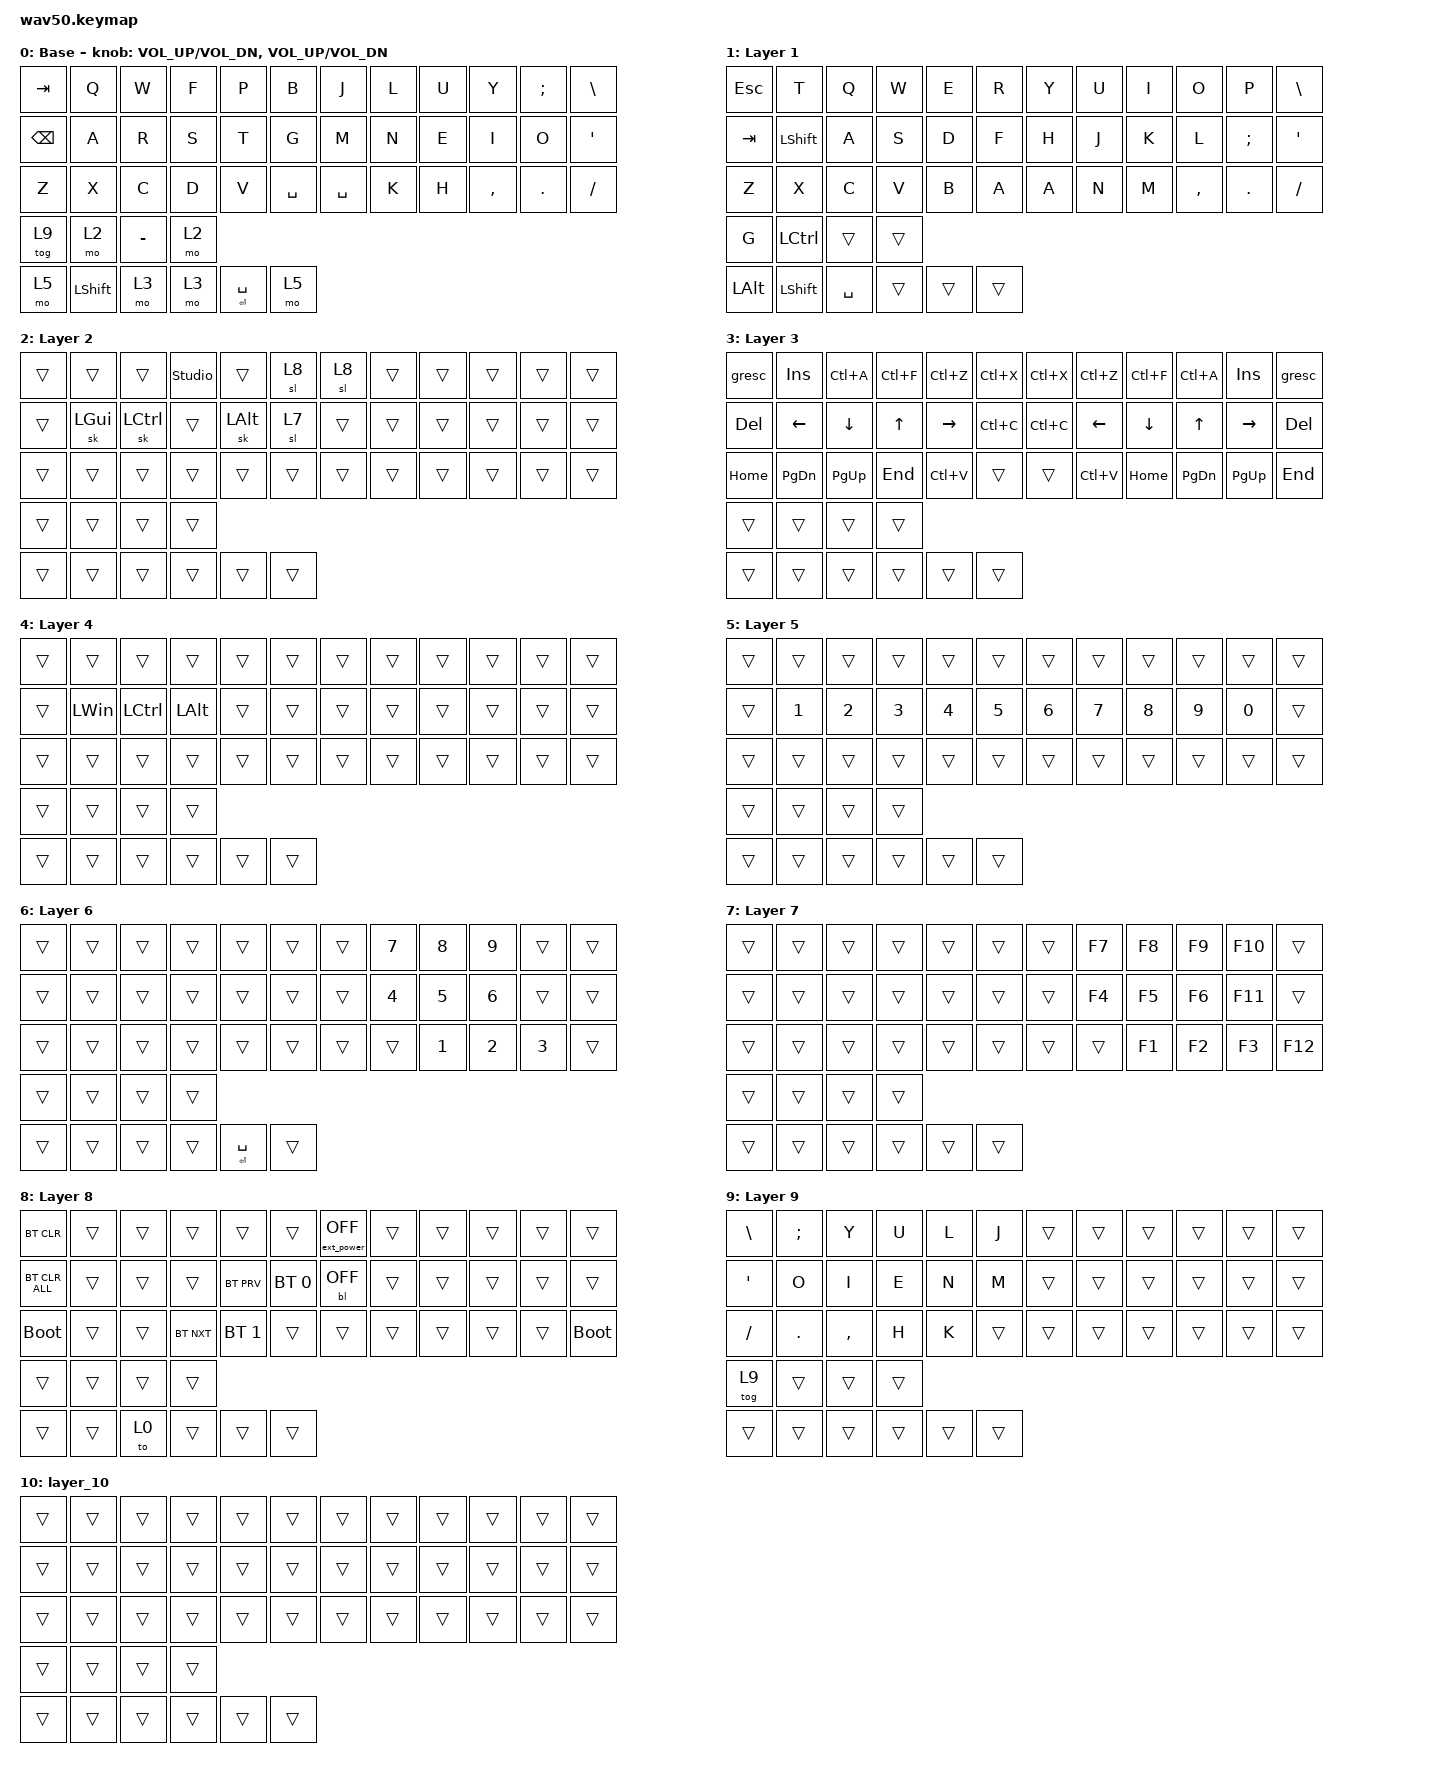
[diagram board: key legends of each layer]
#include <behaviors.dtsi>
#include <dt-bindings/zmk/backlight.h>
#include <dt-bindings/zmk/bt.h>
#include <dt-bindings/zmk/ext_power.h>
#include <dt-bindings/zmk/keys.h>

/ {
    behaviors {
        spc_ent: space_enter {
            compatible = "zmk,behavior-hold-tap";
            #binding-cells = <2>;
            flavor = "tap-preferred";
            tapping-term-ms = <350>;
            bindings = <&kp>, <&kp>;
        };
    };

    keymap {
        compatible = "zmk,keymap";

        default_layer {
            display-name = "Base";
            bindings = <
&kp TAB   &kp Q           &kp W      &kp F  &kp P          &kp B      &kp J      &kp L  &kp U  &kp Y      &kp SEMI  &kp BACKSLASH
&kp BSPC  &kp A           &kp R      &kp S  &kp T          &kp G      &kp M      &kp N  &kp E  &kp I      &kp O     &kp SQT
&kp Z     &kp X           &kp C      &kp D  &kp V          &kp SPACE  &kp SPACE  &kp K  &kp H  &kp COMMA  &kp DOT   &kp FSLH
&tog 9    &mo 2           &kp MINUS  &mo 2
&mo 5     &kp LEFT_SHIFT  &mo 3      &mo 3  &spc_ent RET SPACE  &mo 5
            >;

            sensor-bindings = <&inc_dec_kp C_VOL_UP C_VOL_DN &inc_dec_kp C_VOL_UP C_VOL_DN>;
        };

        low {
            display-name = "Layer 1";
            bindings = <
&kp ESC   &kp T      &kp Q      &kp W   &kp E   &kp R   &kp Y  &kp U  &kp I  &kp O      &kp P     &kp BSLH
&kp TAB   &kp LSHFT  &kp A      &kp S   &kp D   &kp F   &kp H  &kp J  &kp K  &kp L      &kp SEMI  &kp APOS
&kp Z     &kp X      &kp C      &kp V   &kp B   &kp A   &kp A  &kp N  &kp M  &kp COMMA  &kp DOT   &kp FSLH
&kp G     &kp LCTRL  &trans     &trans
&kp LALT  &kp LSHFT  &kp SPACE  &trans  &trans  &trans
            >;
        };

        up {
            display-name = "Layer 2";
            bindings = <
&trans  &trans        &trans            &studio_unlock  &trans        &sl 8   &sl 8   &trans  &trans  &trans  &trans  &trans
&trans  &sk LEFT_GUI  &sk LEFT_CONTROL  &trans          &sk LEFT_ALT  &sl 7   &trans  &trans  &trans  &trans  &trans  &trans
&trans  &trans        &trans            &trans          &trans        &trans  &trans  &trans  &trans  &trans  &trans  &trans
&trans  &trans        &trans            &trans
&trans  &trans        &trans            &trans          &trans        &trans
            >;
        };

        nav {
            display-name = "Layer 3";
            bindings = <
&gresc      &kp INS        &kp LC(A)       &kp LC(F)     &kp LC(Z)        &kp LC(X)  &kp LC(X)  &kp LC(Z)       &kp LC(F)  &kp LC(A)      &kp INS    &gresc
&kp DELETE  &kp LEFT       &kp DOWN_ARROW  &kp UP_ARROW  &kp RIGHT_ARROW  &kp LC(C)  &kp LC(C)  &kp LEFT_ARROW  &kp DOWN   &kp UP_ARROW   &kp RIGHT  &kp DEL
&kp HOME    &kp PAGE_DOWN  &kp PG_UP       &kp END       &kp LC(V)        &trans     &trans     &kp LC(V)       &kp HOME   &kp PAGE_DOWN  &kp PG_UP  &kp END
&trans      &trans         &trans          &trans
&trans      &trans         &trans          &trans        &trans           &trans
            >;
        };

        mods {
            display-name = "Layer 4";
            bindings = <
&trans  &trans        &trans            &trans        &trans  &trans  &trans  &trans  &trans  &trans  &trans  &trans
&trans  &kp LEFT_WIN  &kp LEFT_CONTROL  &kp LEFT_ALT  &trans  &trans  &trans  &trans  &trans  &trans  &trans  &trans
&trans  &trans        &trans            &trans        &trans  &trans  &trans  &trans  &trans  &trans  &trans  &trans
&trans  &trans        &trans            &trans
&trans  &trans        &trans            &trans        &trans  &trans
            >;
        };

        numbers-homerow {
            display-name = "Layer 5";
            bindings = <
&trans  &trans        &trans        &trans        &trans        &trans        &trans        &trans        &trans        &trans        &trans        &trans
&trans  &kp NUMBER_1  &kp NUMBER_2  &kp NUMBER_3  &kp NUMBER_4  &kp NUMBER_5  &kp NUMBER_6  &kp NUMBER_7  &kp NUMBER_8  &kp NUMBER_9  &kp NUMBER_0  &trans
&trans  &trans        &trans        &trans        &trans        &trans        &trans        &trans        &trans        &trans        &trans        &trans
&trans  &trans        &trans        &trans
&trans  &trans        &trans        &trans        &trans        &trans
            >;
        };

        numpad {
            display-name = "Layer 6";
            bindings = <
&trans  &trans  &trans  &trans  &trans           &trans  &trans  &kp NUMBER_7  &kp NUMBER_8  &kp NUMBER_9  &trans        &trans
&trans  &trans  &trans  &trans  &trans           &trans  &trans  &kp NUMBER_4  &kp NUMBER_5  &kp NUMBER_6  &trans        &trans
&trans  &trans  &trans  &trans  &trans           &trans  &trans  &trans        &kp NUMBER_1  &kp NUMBER_2  &kp NUMBER_3  &trans
&trans  &trans  &trans  &trans
&trans  &trans  &trans  &trans  &spc_ent ENTER SPACE  &trans
            >;
        };

        function {
            display-name = "Layer 7";
            bindings = <
&trans  &trans  &trans  &trans  &trans  &trans  &trans  &kp F7  &kp F8  &kp F9  &kp F10  &trans
&trans  &trans  &trans  &trans  &trans  &trans  &trans  &kp F4  &kp F5  &kp F6  &kp F11  &trans
&trans  &trans  &trans  &trans  &trans  &trans  &trans  &trans  &kp F1  &kp F2  &kp F3   &kp F12
&trans  &trans  &trans  &trans
&trans  &trans  &trans  &trans  &trans  &trans
            >;
        };

        settings {
            display-name = "Layer 8";
            bindings = <
&bt BT_CLR      &trans  &trans  &trans      &trans        &trans        &ext_power EP_OFF  &trans  &trans  &trans  &trans  &trans
&bt BT_CLR_ALL  &trans  &trans  &trans      &bt BT_PRV    &bt BT_SEL 0  &bl BL_OFF         &trans  &trans  &trans  &trans  &trans
&bootloader     &trans  &trans  &bt BT_NXT  &bt BT_SEL 1  &trans        &trans             &trans  &trans  &trans  &trans  &bootloader
&trans          &trans  &trans  &trans
&trans          &trans  &to 0   &trans      &trans        &trans
            >;
        };

        mirror-onehand {
            display-name = "Layer 9";
            bindings = <
&kp BSLH  &kp SEMI  &kp Y      &kp U   &kp L   &kp J   &trans  &trans  &trans  &trans  &trans  &trans
&kp SQT   &kp O     &kp I      &kp E   &kp N   &kp M   &trans  &trans  &trans  &trans  &trans  &trans
&kp FSLH  &kp DOT   &kp COMMA  &kp H   &kp K   &trans  &trans  &trans  &trans  &trans  &trans  &trans
&tog 9    &trans    &trans     &trans
&trans    &trans    &trans     &trans  &trans  &trans
            >;
        };

        layer_10 {
            bindings = <
&trans  &trans  &trans  &trans  &trans  &trans  &trans  &trans  &trans  &trans  &trans  &trans
&trans  &trans  &trans  &trans  &trans  &trans  &trans  &trans  &trans  &trans  &trans  &trans
&trans  &trans  &trans  &trans  &trans  &trans  &trans  &trans  &trans  &trans  &trans  &trans
&trans  &trans  &trans  &trans
&trans  &trans  &trans  &trans  &trans  &trans
            >;
        };
    };
};
